# ipro6s register map
Vendor: intelpro; Series: IPRO6S
CPU: ipro6s, little endian
Registers are 32-bit, read-write, reset 0x0 unless marked. A register's access mark holds for its fields unless they carry their own. Offsets are from the block's base; [hi:lo] are bit positions; {n}, {i} and the like mark numbered series.

## MJCOMB_CSR
Base 0x3001A000
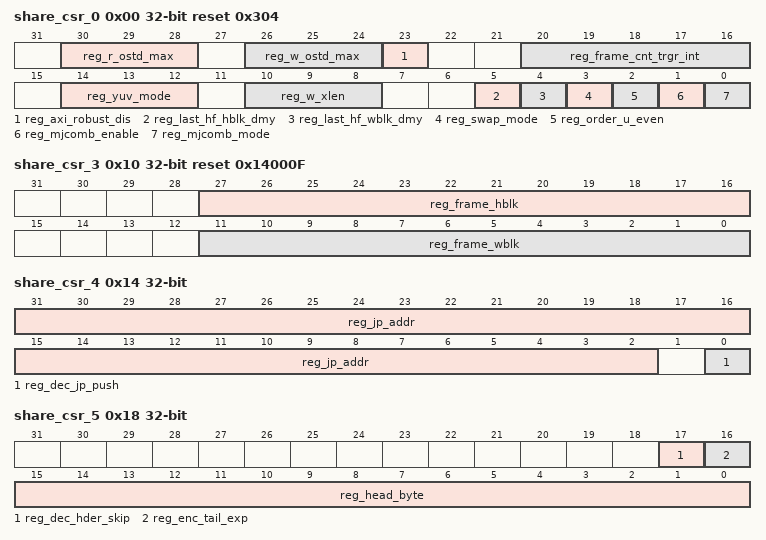
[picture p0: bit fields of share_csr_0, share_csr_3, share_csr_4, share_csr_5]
0x00 share_csr_0 reset 0x304
  [30:28] reg_r_ostd_max — Reserved for HW
  [26:24] reg_w_ostd_max — Reserved for HW
  [23] reg_axi_robust_dis — Reserved for HW
  [20:16] reg_frame_cnt_trgr_int — Frame threshold to issue interrupt
  [14:12] reg_yuv_mode — YUV format setting 3'd0 : YUV420 Semi-Planar 3'd1 : YUV400 grey scale 3'd2 : YUV422 Semi-Planar 3'd3 : INTV422 (Only for JENC) 3'd4 : YUV420 Block mode (Only for JENC) others : Reserved
  [10:8] reg_w_xlen — AXI burst length setting 3'd0-Single / 3'd1-INCR4 / 3'd2-INCR8 3'd3 - INCR16 / Others - RSVD
  [5] reg_last_hf_hblk_dmy — MJPEG last half vertical block with dummy data 8'h80
  [4] reg_last_hf_wblk_dmy — MJPEG last half horizational block with dummy data 8'h80
  [3] reg_swap_mode — ENC : Bitstream write swap mode JDEC YUV Memory swap mode
  [2] reg_order_u_even — 1'b0 - U is odd byte of UV frame / V is even byte of UV frame 1'b1 - U is even byte of UV frame / V is odd byte of UV frame
  [1] reg_mjcomb_enable — MJPEG enable
  [0] reg_mjcomb_mode — MJPEG Mode 1'b0 - Encode mode 1'b1 - Decode mode
0x08 share_csr_1 reset 0x80000000
  [31:0] reg_yy_addr_start — Memory start address of Y frame
0x0C share_csr_2 reset 0x80000000
  [31:0] reg_uv_addr_start — Memory start address of UV frame
0x10 share_csr_3 reset 0x14000F
  [27:16] reg_frame_hblk — Frame total vertical block count
  [11:0] reg_frame_wblk — Frame total horizational block count
0x14 share_csr_4
  [31:2] reg_jp_addr — Memory start address of JPEG stream Decode :
  [0] reg_dec_jp_push wo — (only for Decode)Wrire this bit with 1'b1 to push jpg frame
0x18 share_csr_5
  [17] reg_dec_hder_skip — Skip JPEG stream header enable
  [16] reg_enc_tail_exp — Auto fill tail 0xFF and 0xD9
  [15:0] reg_head_byte — ENC - Preserve head memory space for each frame DEC - Skip JPEG stream header byte
0x40 jstr_check_sum reset not defined
  [31:0] st_jstr_check_sum ro — check sum result
0x44 jstr_check_xor reset not defined
  [31:0] st_jstr_check_xor ro — check sum result
0x48 yuv_check_sum reset not defined
  [31:0] st_yuv_check_sum ro — check sum result
0x4C yuv_check_xor reset not defined
  [31:0] st_yuv_check_xor ro — check sum result
0x7C share_csr_e reset 0xF0
  [7:0] dummy_reg — Dummy R/W register
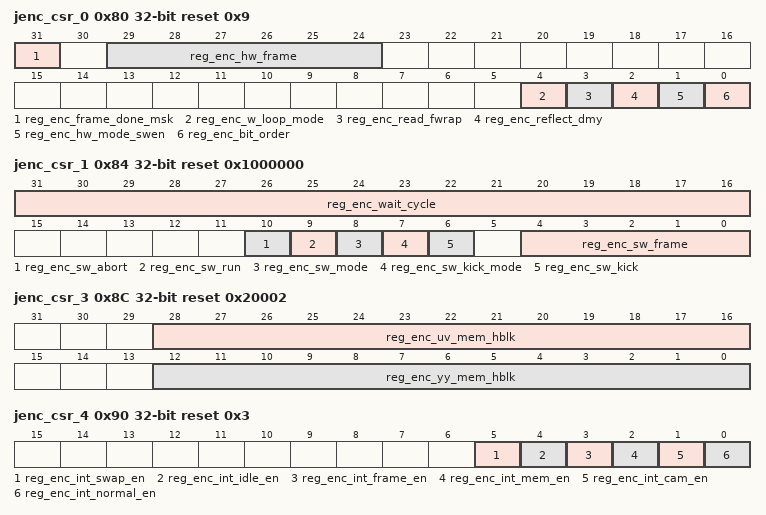
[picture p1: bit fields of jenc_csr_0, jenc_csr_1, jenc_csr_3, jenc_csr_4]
0x80 jenc_csr_0 reset 0x9
  [31] reg_enc_frame_done_msk — Reserved for HW option
  [29:24] reg_enc_hw_frame — Non-SW mode frame cnt 0 - Non auto stop
  [4] reg_enc_w_loop_mode — Write bitstream loop mode enable
  [3] reg_enc_read_fwrap — Only effect in non SW mode This bit determine whether YUV frame read start @ start address
  [2] reg_enc_reflect_dmy — UV dummy with relect
  [1] reg_enc_hw_mode_swen — Only word In hardware mode. SW enable immediately to skip waiting first frame done
  [0] reg_enc_bit_order — MJPEG bitstream byte order adjustment
0x84 jenc_csr_1 reset 0x1000000
  [31:16] reg_enc_wait_cycle — Cycle count in wait state
  [10] reg_enc_sw_abort — MJPEG SW mode abort
  [9] reg_enc_sw_run — MJPEG SW mode run (should enable reg_mjpeg_sw_mode before reg_mjpeg_sw_run)
  [8] reg_enc_sw_mode — MJPEG SW mode enable (should enable reg_mjpeg_sw_mode before reg_mjpeg_sw_run)
  [7] reg_enc_sw_kick_mode — MJPEG SW mode hblk kick mode 1'b0 - SW frame mode 1'b1 - SW kick mode
  [6] reg_enc_sw_kick wo — MJPEG SW mode hblk kick
  [4:0] reg_enc_sw_frame — MJPEG SW mode frame count Only effect when reg_enc_sw_mode==1 && reg_enc_sw_kick_mode==0
0x88 jenc_csr_2 reset 0x4000
  [31:0] reg_enc_jstr_burst_cnt — Memory to store jpeg image burst count
0x8C jenc_csr_3 reset 0x20002
  [28:16] reg_enc_uv_mem_hblk — Memory to store block line for UV frame
  [12:0] reg_enc_yy_mem_hblk — Memory to store block line for Y frame
0x90 jenc_csr_4 reset 0x3
  [5] reg_enc_int_swap_en — Swap memory block interrupt enable
  [4] reg_enc_int_idle_en — Back idle interrupt enable
  [3] reg_enc_int_frame_en — Frame OverWrite interrupt enable
  [2] reg_enc_int_mem_en — JPEG frame memory OverWrite interrupt enable
  [1] reg_enc_int_cam_en — YUV frame memory OverWrite interrupt enable (fatal)
  [0] reg_enc_int_normal_en — Normal Write interrupt enable
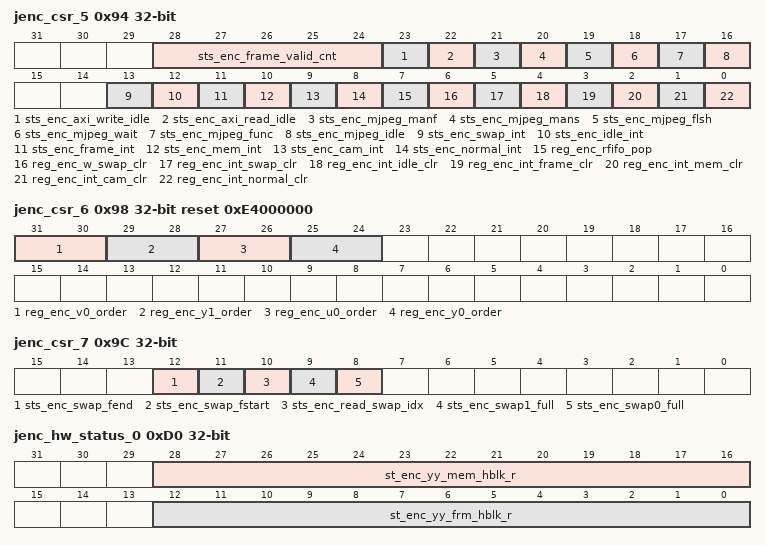
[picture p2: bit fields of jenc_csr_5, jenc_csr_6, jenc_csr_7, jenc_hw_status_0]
0x94 jenc_csr_5 (reset mask 0xFF)
  [28:24] sts_enc_frame_valid_cnt ro — Frame count valid in status
  [23] sts_enc_axi_write_idle ro — AXI write bus idle state
  [22] sts_enc_axi_read_idle ro — AXI read bus idle state
  [21] sts_enc_mjpeg_manf ro — MJPEG in SW run state
  [20] sts_enc_mjpeg_mans ro — MJPEG in SW set state
  [19] sts_enc_mjpeg_flsh ro — MJPEG in flush state
  [18] sts_enc_mjpeg_wait ro — MJPEG in wait state
  [17] sts_enc_mjpeg_func ro — MJPEG in HW function state
  [16] sts_enc_mjpeg_idle ro — MJPEG in idle state
  [13] sts_enc_swap_int ro — Swap memory block interrupt status
  [12] sts_enc_idle_int ro — Normal Write interrupt status
  [11] sts_enc_frame_int ro — Frame OverWrite interrupt status
  [10] sts_enc_mem_int ro — Memory OverWrite interrupt status
  [9] sts_enc_cam_int ro — CAM OverWrite interrupt status (fatal)
  [8] sts_enc_normal_int ro — Normal Write interrupt status
  [7] reg_enc_rfifo_pop wo — Write this bit with 1'b1 to trigger JPEG frame fifo pop
  [6] reg_enc_w_swap_clr wo — Free current read memory block
  [5] reg_enc_int_swap_clr wo — Wrire this bit with 1'b1 to trigger swap interrupt clear
  [4] reg_enc_int_idle_clr wo — Wrire this bit with 1'b1 to trigger back idle interrupt clear
  [3] reg_enc_int_frame_clr wo — Wrire this bit with 1'b1 to trigger frame overwrite interrupt clear
  [2] reg_enc_int_mem_clr wo — Wrire this bit with 1'b1 to trigger memory overwrite interrupt clear
  [1] reg_enc_int_cam_clr wo — Wrire this bit with 1'b1 to trigger YUV overwrite interrupt clear
  [0] reg_enc_int_normal_clr wo — Wrire this bit with 1'b1 to trigger normal interrupt clear
0x98 jenc_csr_6 reset 0xE4000000
  [31:30] reg_enc_v0_order — V order in Interleave mode (only effect when reg_yuv_mode==INTV422)
  [29:28] reg_enc_y1_order — Y1 order in Interleave mode (only effect when reg_yuv_mode==INTV422)
  [27:26] reg_enc_u0_order — U order in Interleave mode (only effect when reg_yuv_mode==INTV422)
  [25:24] reg_enc_y0_order — Y0 order in Interleave mode (only effect when reg_yuv_mode==INTV422)
0x9C jenc_csr_7 reset not defined
  [12] sts_enc_swap_fend ro — Current read memory block is frame end
  [11] sts_enc_swap_fstart ro — Current read memory block is frame start
  [10] sts_enc_read_swap_idx ro — Current read memory block index 0 - memory block0 1 - memory block1
  [9] sts_enc_swap1_full ro — Memory block1 is full
  [8] sts_enc_swap0_full ro — Memory block0 is full
0xA0 jenc_csr_8 reset not defined
  [31:0] sts_enc_frame_swap_end_bit_cnt ro — In swap mode frame remain bit count in last block Only valid when "sts_swap_fend==1"
0xA4 jenc_csr_9 reset 0x2
  [12:0] reg_enc_sw_kick_hblk — Memory to store block line for frame on SW kick
0xA8 jenc_csr_10 reset not defined
  [31:0] sts_enc_frame_start_addr_0 ro — MJPEG FRAME0 Start address
0xAC jenc_csr_11 reset not defined
  [31:0] sts_enc_frame_bit_cnt_0 ro — MJPEG FRAME0 total bit count
0xB0 jenc_csr_12 reset not defined
  [31:0] sts_enc_frame_start_addr_1 ro — MJPEG FRAME1 Start address
0xB4 jenc_csr_13 reset not defined
  [31:0] sts_enc_frame_bit_cnt_1 ro — MJPEG FRAME1 total bit count
0xB8 jenc_csr_14 reset not defined
  [31:0] sts_enc_frame_start_addr_2 ro — MJPEG FRAME2 Start address
0xBC jenc_csr_15 reset not defined
  [31:0] sts_enc_frame_bit_cnt_2 ro — MJPEG FRAME2 total bit count
0xC0 jenc_csr_16 reset not defined
  [31:0] sts_enc_frame_start_addr_3 ro — MJPEG FRAME3 Start address
0xC4 jenc_csr_17 reset not defined
  [31:0] sts_enc_frame_bit_cnt_3 ro — MJPEG FRAME3 total bit count
0xD0 jenc_hw_status_0 reset not defined
  [28:16] st_enc_yy_mem_hblk_r ro — HW status
  [12:0] st_enc_yy_frm_hblk_r ro — HW status
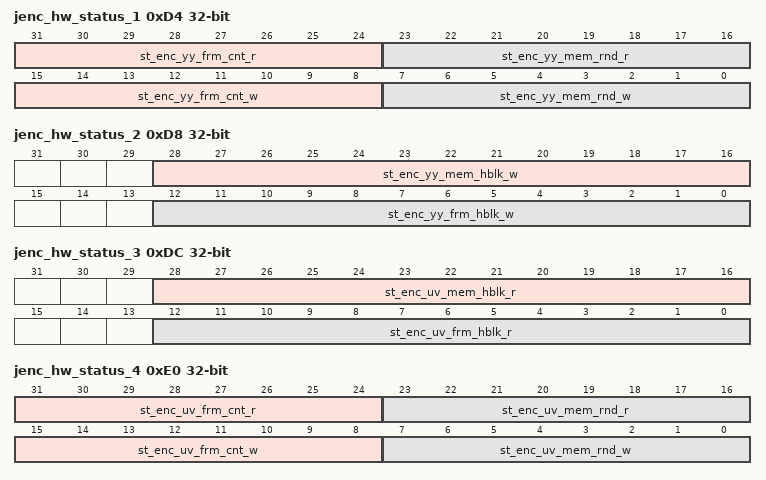
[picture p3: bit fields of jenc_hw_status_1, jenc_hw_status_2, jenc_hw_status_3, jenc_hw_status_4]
0xD4 jenc_hw_status_1 reset not defined
  [31:24] st_enc_yy_frm_cnt_r ro — HW status
  [23:16] st_enc_yy_mem_rnd_r ro — HW status
  [15:8] st_enc_yy_frm_cnt_w ro — HW status
  [7:0] st_enc_yy_mem_rnd_w ro — HW status
0xD8 jenc_hw_status_2 reset not defined
  [28:16] st_enc_yy_mem_hblk_w ro — HW status
  [12:0] st_enc_yy_frm_hblk_w ro — HW status
0xDC jenc_hw_status_3 reset not defined
  [28:16] st_enc_uv_mem_hblk_r ro — HW status
  [12:0] st_enc_uv_frm_hblk_r ro — HW status
0xE0 jenc_hw_status_4 reset not defined
  [31:24] st_enc_uv_frm_cnt_r ro — HW status
  [23:16] st_enc_uv_mem_rnd_r ro — HW status
  [15:8] st_enc_uv_frm_cnt_w ro — HW status
  [7:0] st_enc_uv_mem_rnd_w ro — HW status
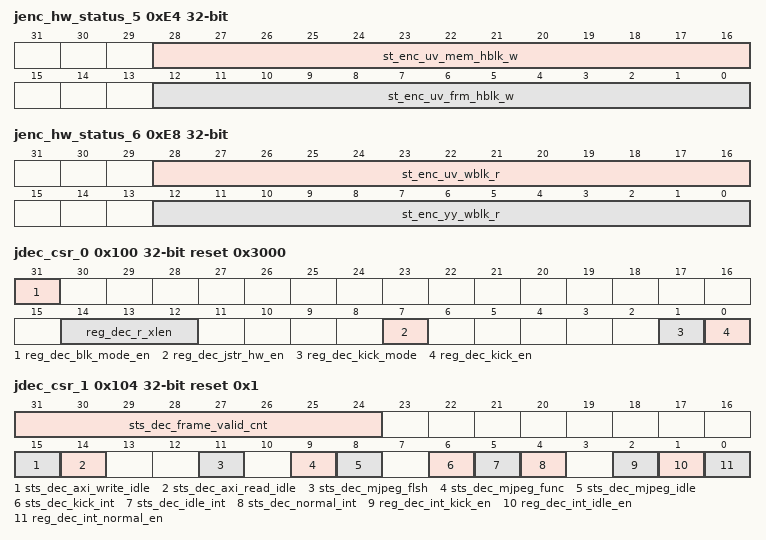
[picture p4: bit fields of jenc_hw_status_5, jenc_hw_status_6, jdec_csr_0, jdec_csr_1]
0xE4 jenc_hw_status_5 reset not defined
  [28:16] st_enc_uv_mem_hblk_w ro — HW status
  [12:0] st_enc_uv_frm_hblk_w ro — HW status
0xE8 jenc_hw_status_6 reset not defined
  [28:16] st_enc_uv_wblk_r ro — HW status
  [12:0] st_enc_yy_wblk_r ro — HW status
0x100 jdec_csr_0 reset 0x3000
  [31] reg_dec_blk_mode_en — JDEC block output mode enable
  [14:12] reg_dec_r_xlen — AXI read burst length setting 3'd0-Single / 3'd1-INCR4 / 3'd2-INCR8 3'd3 - INCR16 / Others - RSVD
  [7] reg_dec_jstr_hw_en — JDEC auto co-work with encode engine mode enable
  [1] reg_dec_kick_mode — JDEC SW control flow kick unit : YUV422 - 1'b0 : Y - 128x8 / UV - 128x8 1'b1 : Block line mode YUV420 - 1'b0 : Y - 128x16 / UV - 128x8 1'b1 : Block line mode
  [0] reg_dec_kick_en — JDEC SW control flow kick mode enable
0x104 jdec_csr_1 reset 0x1 (reset mask 0x7)
  [31:24] sts_dec_frame_valid_cnt ro — Frame count valid in status
  [15] sts_dec_axi_write_idle ro — AXI write bus idle state
  [14] sts_dec_axi_read_idle ro — AXI read bus idle state
  [11] sts_dec_mjpeg_flsh ro — MJPEG in flush state
  [9] sts_dec_mjpeg_func ro — MJPEG in HW function state
  [8] sts_dec_mjpeg_idle ro — MJPEG in idle state
  [6] sts_dec_kick_int ro — Interrupt status
  [5] sts_dec_idle_int ro — Interrupt status
  [4] sts_dec_normal_int ro — Interrupt status
  [2] reg_dec_int_kick_en — Kick mode interrupt enable
  [1] reg_dec_int_idle_en — Back idle interrupt enable
  [0] reg_dec_int_normal_en — Normal Write interrupt enable
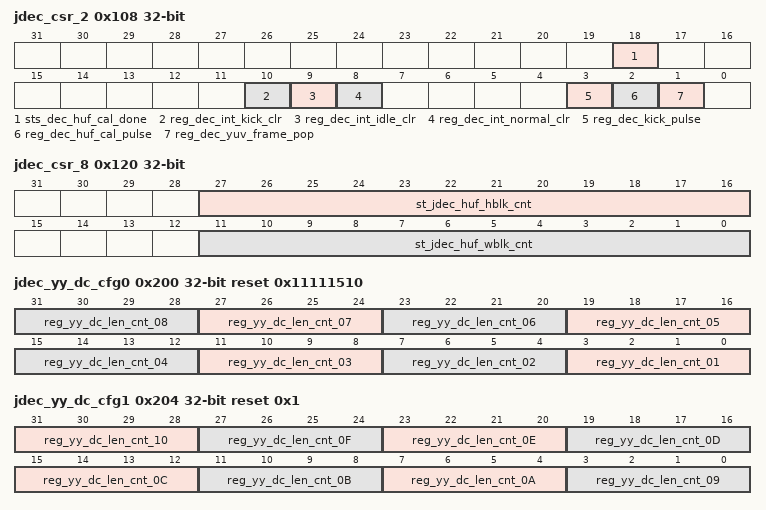
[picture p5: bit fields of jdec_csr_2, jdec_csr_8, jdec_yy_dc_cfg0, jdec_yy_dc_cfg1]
0x108 jdec_csr_2 (reset mask 0x70E)
  [18] sts_dec_huf_cal_done ro — Huffman Table calculation done
  [10] reg_dec_int_kick_clr wo — Wrire this bit with 1'b1 to trigger interrupt clear
  [9] reg_dec_int_idle_clr wo — Wrire this bit with 1'b1 to trigger interrupt clear
  [8] reg_dec_int_normal_clr wo — Wrire this bit with 1'b1 to trigger interrupt clear
  [3] reg_dec_kick_pulse wo — JDEC SW control flow kick mode - SW kick to enable one hblk line write out
  [2] reg_dec_huf_cal_pulse wo — Huffman Table calculation
  [1] reg_dec_yuv_frame_pop wo — Wrire this bit with 1'b1 to pop yuv frame cnt
0x10C jdec_csr_3 reset not defined
  [2:0] sts_dec_jp_frame_cnt ro — JPEG FIFO frame cnt
{0x100+4i} jdec_csr_{i} reset not defined (i=4..7)
  [31:0] sts_dec_jp_addr_{i-4} ro — JPEG PIC {i-4} Start address
0x120 jdec_csr_8 reset not defined
  [27:16] st_jdec_huf_hblk_cnt ro — HW status
  [11:0] st_jdec_huf_wblk_cnt ro — HW status
0x200 jdec_yy_dc_cfg0 reset 0x11111510
  [4n-1:4n-4] reg_yy_dc_len_cnt_{n:02} (n=1..8) — Length count of huffman table
0x204 jdec_yy_dc_cfg1 reset 0x1
  [31:28] reg_yy_dc_len_cnt_10 — Length count of huffman table
  [27:24] reg_yy_dc_len_cnt_0F — Length count of huffman table
  [23:20] reg_yy_dc_len_cnt_0E — Length count of huffman table
  [19:16] reg_yy_dc_len_cnt_0D — Length count of huffman table
  [15:12] reg_yy_dc_len_cnt_0C — Length count of huffman table
  [11:8] reg_yy_dc_len_cnt_0B — Length count of huffman table
  [7:4] reg_yy_dc_len_cnt_0A — Length count of huffman table
  [3:0] reg_yy_dc_len_cnt_09 — Length count of huffman table
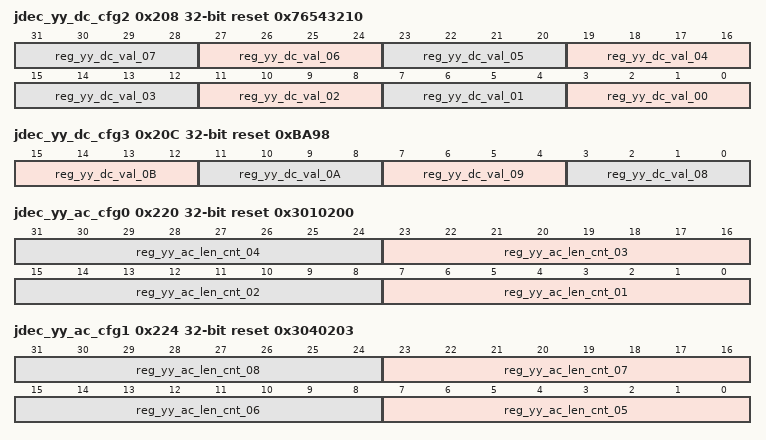
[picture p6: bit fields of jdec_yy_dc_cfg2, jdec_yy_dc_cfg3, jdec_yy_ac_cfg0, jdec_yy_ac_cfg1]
0x208 jdec_yy_dc_cfg2 reset 0x76543210
  [4n+3:4n] reg_yy_dc_val_{n:02} (n=0..7) — Value of huffman table
0x20C jdec_yy_dc_cfg3 reset 0xBA98
  [15:12] reg_yy_dc_val_0B — Value of huffman table
  [11:8] reg_yy_dc_val_0A — Value of huffman table
  [7:4] reg_yy_dc_val_09 — Value of huffman table
  [3:0] reg_yy_dc_val_08 — Value of huffman table
0x220 jdec_yy_ac_cfg0 reset 0x3010200
  [8n-1:8n-8] reg_yy_ac_len_cnt_{n:02} (n=1..4) — Length count of huffman table
0x224 jdec_yy_ac_cfg1 reset 0x3040203
  [8n-33:8n-40] reg_yy_ac_len_cnt_{n:02} (n=5..8) — Length count of huffman table
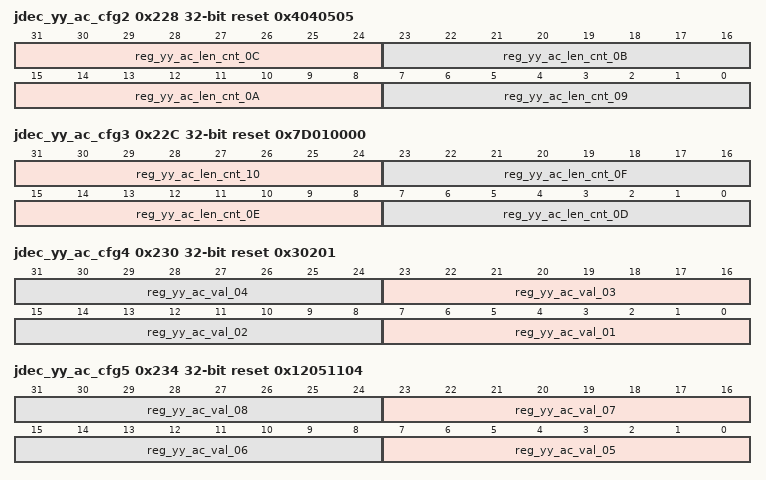
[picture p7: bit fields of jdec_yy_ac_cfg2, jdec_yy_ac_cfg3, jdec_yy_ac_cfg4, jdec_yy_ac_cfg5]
0x228 jdec_yy_ac_cfg2 reset 0x4040505
  [31:24] reg_yy_ac_len_cnt_0C — Length count of huffman table
  [23:16] reg_yy_ac_len_cnt_0B — Length count of huffman table
  [15:8] reg_yy_ac_len_cnt_0A — Length count of huffman table
  [7:0] reg_yy_ac_len_cnt_09 — Length count of huffman table
0x22C jdec_yy_ac_cfg3 reset 0x7D010000
  [31:24] reg_yy_ac_len_cnt_10 — Length count of huffman table
  [23:16] reg_yy_ac_len_cnt_0F — Length count of huffman table
  [15:8] reg_yy_ac_len_cnt_0E — Length count of huffman table
  [7:0] reg_yy_ac_len_cnt_0D — Length count of huffman table
0x230 jdec_yy_ac_cfg4 reset 0x30201
  [8n-1:8n-8] reg_yy_ac_val_{n:02} (n=1..4) — Value of huffman table
0x234 jdec_yy_ac_cfg5 reset 0x12051104
  [8n-33:8n-40] reg_yy_ac_val_{n:02} (n=5..8) — Value of huffman table
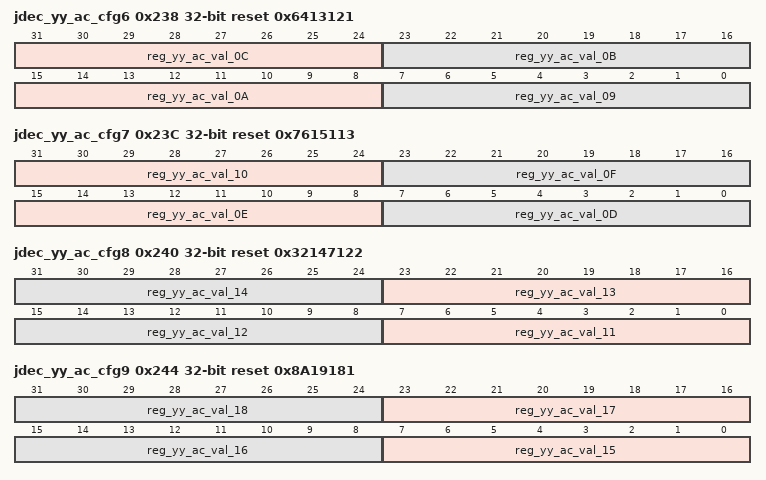
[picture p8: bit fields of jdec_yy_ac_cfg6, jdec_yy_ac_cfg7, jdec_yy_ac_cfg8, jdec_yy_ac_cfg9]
0x238 jdec_yy_ac_cfg6 reset 0x6413121
  [31:24] reg_yy_ac_val_0C — Value of huffman table
  [23:16] reg_yy_ac_val_0B — Value of huffman table
  [15:8] reg_yy_ac_val_0A — Value of huffman table
  [7:0] reg_yy_ac_val_09 — Value of huffman table
0x23C jdec_yy_ac_cfg7 reset 0x7615113
  [31:24] reg_yy_ac_val_10 — Value of huffman table
  [23:16] reg_yy_ac_val_0F — Value of huffman table
  [15:8] reg_yy_ac_val_0E — Value of huffman table
  [7:0] reg_yy_ac_val_0D — Value of huffman table
0x240 jdec_yy_ac_cfg8 reset 0x32147122
  [8n-81:8n-88] reg_yy_ac_val_{n} (n=11..14) — Value of huffman table
0x244 jdec_yy_ac_cfg9 reset 0x8A19181
  [8n-113:8n-120] reg_yy_ac_val_{n} (n=15..18) — Value of huffman table
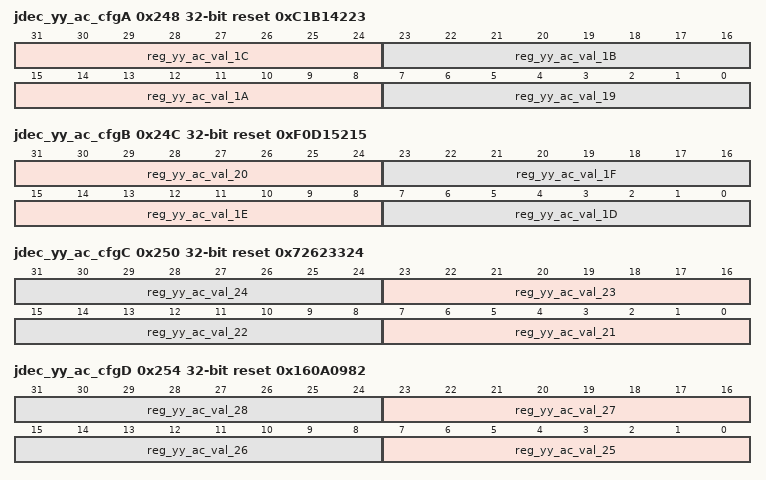
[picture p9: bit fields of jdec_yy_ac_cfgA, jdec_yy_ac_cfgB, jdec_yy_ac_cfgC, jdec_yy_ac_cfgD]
0x248 jdec_yy_ac_cfgA reset 0xC1B14223
  [31:24] reg_yy_ac_val_1C — Value of huffman table
  [23:16] reg_yy_ac_val_1B — Value of huffman table
  [15:8] reg_yy_ac_val_1A — Value of huffman table
  [7:0] reg_yy_ac_val_19 — Value of huffman table
0x24C jdec_yy_ac_cfgB reset 0xF0D15215
  [31:24] reg_yy_ac_val_20 — Value of huffman table
  [23:16] reg_yy_ac_val_1F — Value of huffman table
  [15:8] reg_yy_ac_val_1E — Value of huffman table
  [7:0] reg_yy_ac_val_1D — Value of huffman table
0x250 jdec_yy_ac_cfgC reset 0x72623324
  [8n-161:8n-168] reg_yy_ac_val_{n} (n=21..24) — Value of huffman table
0x254 jdec_yy_ac_cfgD reset 0x160A0982
  [8n-193:8n-200] reg_yy_ac_val_{n} (n=25..28) — Value of huffman table
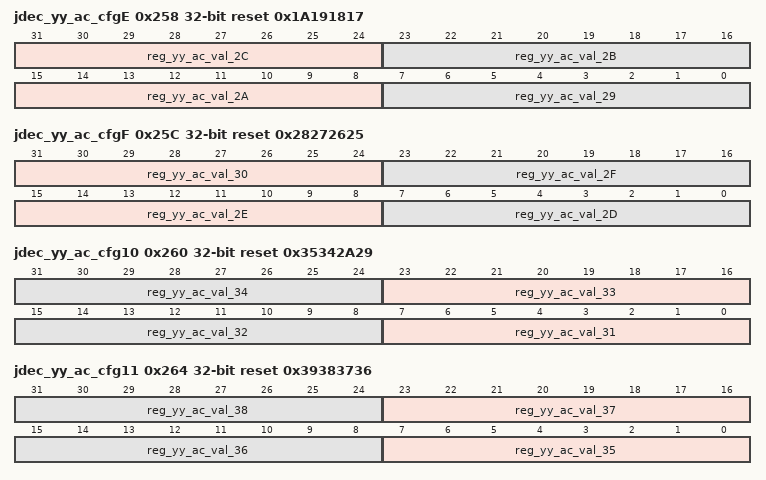
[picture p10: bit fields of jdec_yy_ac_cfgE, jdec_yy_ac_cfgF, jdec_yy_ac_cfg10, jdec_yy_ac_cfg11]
0x258 jdec_yy_ac_cfgE reset 0x1A191817
  [31:24] reg_yy_ac_val_2C — Value of huffman table
  [23:16] reg_yy_ac_val_2B — Value of huffman table
  [15:8] reg_yy_ac_val_2A — Value of huffman table
  [7:0] reg_yy_ac_val_29 — Value of huffman table
0x25C jdec_yy_ac_cfgF reset 0x28272625
  [31:24] reg_yy_ac_val_30 — Value of huffman table
  [23:16] reg_yy_ac_val_2F — Value of huffman table
  [15:8] reg_yy_ac_val_2E — Value of huffman table
  [7:0] reg_yy_ac_val_2D — Value of huffman table
0x260 jdec_yy_ac_cfg10 reset 0x35342A29
  [8n-241:8n-248] reg_yy_ac_val_{n} (n=31..34) — Value of huffman table
0x264 jdec_yy_ac_cfg11 reset 0x39383736
  [8n-273:8n-280] reg_yy_ac_val_{n} (n=35..38) — Value of huffman table
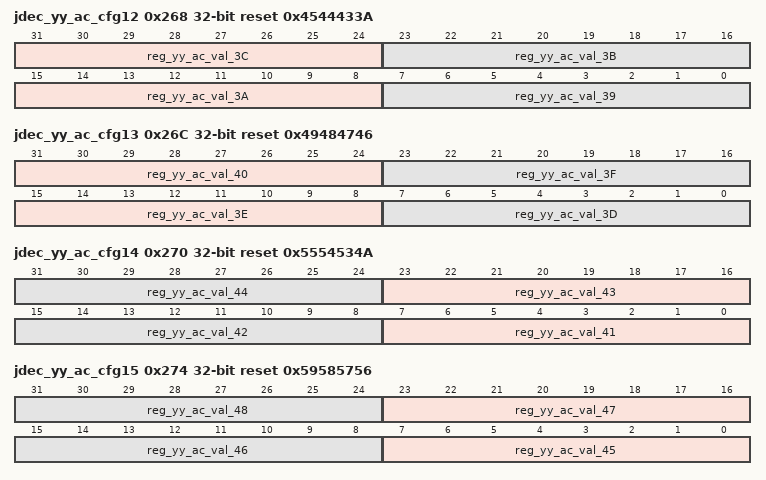
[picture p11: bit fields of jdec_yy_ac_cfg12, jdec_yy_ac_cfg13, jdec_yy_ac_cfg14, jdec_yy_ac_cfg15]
0x268 jdec_yy_ac_cfg12 reset 0x4544433A
  [31:24] reg_yy_ac_val_3C — Value of huffman table
  [23:16] reg_yy_ac_val_3B — Value of huffman table
  [15:8] reg_yy_ac_val_3A — Value of huffman table
  [7:0] reg_yy_ac_val_39 — Value of huffman table
0x26C jdec_yy_ac_cfg13 reset 0x49484746
  [31:24] reg_yy_ac_val_40 — Value of huffman table
  [23:16] reg_yy_ac_val_3F — Value of huffman table
  [15:8] reg_yy_ac_val_3E — Value of huffman table
  [7:0] reg_yy_ac_val_3D — Value of huffman table
0x270 jdec_yy_ac_cfg14 reset 0x5554534A
  [8n-321:8n-328] reg_yy_ac_val_{n} (n=41..44) — Value of huffman table
0x274 jdec_yy_ac_cfg15 reset 0x59585756
  [8n-353:8n-360] reg_yy_ac_val_{n} (n=45..48) — Value of huffman table
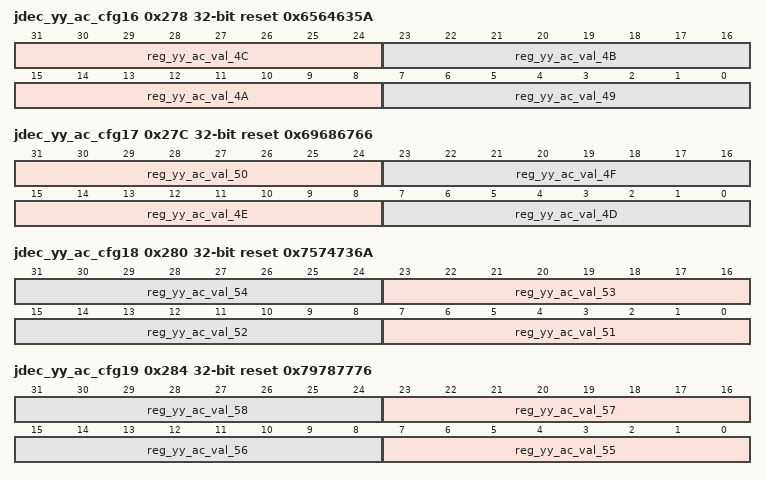
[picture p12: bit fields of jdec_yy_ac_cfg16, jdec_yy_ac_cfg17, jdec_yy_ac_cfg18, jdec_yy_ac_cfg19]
0x278 jdec_yy_ac_cfg16 reset 0x6564635A
  [31:24] reg_yy_ac_val_4C — Value of huffman table
  [23:16] reg_yy_ac_val_4B — Value of huffman table
  [15:8] reg_yy_ac_val_4A — Value of huffman table
  [7:0] reg_yy_ac_val_49 — Value of huffman table
0x27C jdec_yy_ac_cfg17 reset 0x69686766
  [31:24] reg_yy_ac_val_50 — Value of huffman table
  [23:16] reg_yy_ac_val_4F — Value of huffman table
  [15:8] reg_yy_ac_val_4E — Value of huffman table
  [7:0] reg_yy_ac_val_4D — Value of huffman table
0x280 jdec_yy_ac_cfg18 reset 0x7574736A
  [8n-401:8n-408] reg_yy_ac_val_{n} (n=51..54) — Value of huffman table
0x284 jdec_yy_ac_cfg19 reset 0x79787776
  [8n-433:8n-440] reg_yy_ac_val_{n} (n=55..58) — Value of huffman table
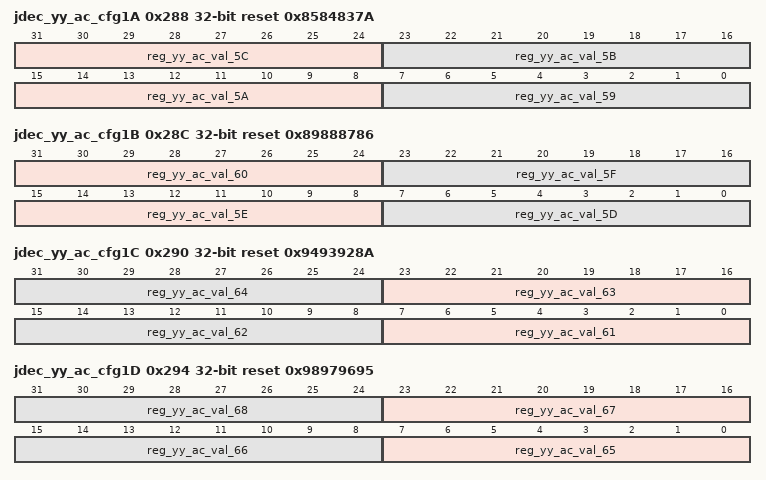
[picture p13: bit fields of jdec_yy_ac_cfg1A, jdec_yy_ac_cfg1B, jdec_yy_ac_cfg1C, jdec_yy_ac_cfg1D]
0x288 jdec_yy_ac_cfg1A reset 0x8584837A
  [31:24] reg_yy_ac_val_5C — Value of huffman table
  [23:16] reg_yy_ac_val_5B — Value of huffman table
  [15:8] reg_yy_ac_val_5A — Value of huffman table
  [7:0] reg_yy_ac_val_59 — Value of huffman table
0x28C jdec_yy_ac_cfg1B reset 0x89888786
  [31:24] reg_yy_ac_val_60 — Value of huffman table
  [23:16] reg_yy_ac_val_5F — Value of huffman table
  [15:8] reg_yy_ac_val_5E — Value of huffman table
  [7:0] reg_yy_ac_val_5D — Value of huffman table
0x290 jdec_yy_ac_cfg1C reset 0x9493928A
  [8n-481:8n-488] reg_yy_ac_val_{n} (n=61..64) — Value of huffman table
0x294 jdec_yy_ac_cfg1D reset 0x98979695
  [8n-513:8n-520] reg_yy_ac_val_{n} (n=65..68) — Value of huffman table
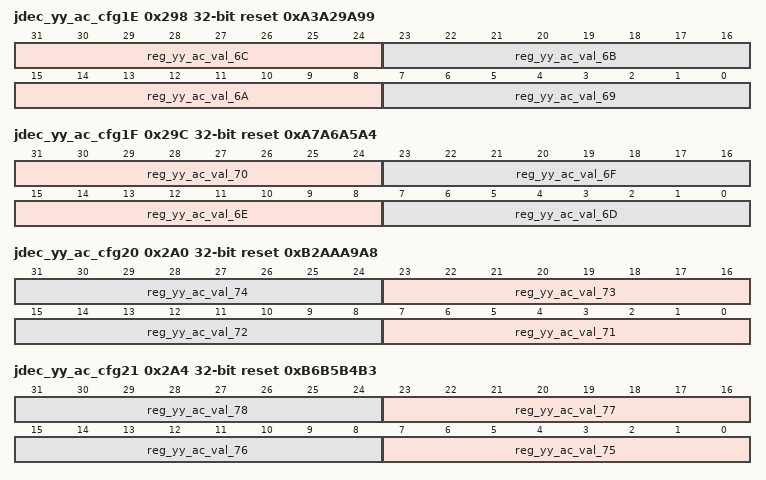
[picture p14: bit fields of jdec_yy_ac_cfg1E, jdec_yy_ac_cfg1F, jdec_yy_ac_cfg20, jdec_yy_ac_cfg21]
0x298 jdec_yy_ac_cfg1E reset 0xA3A29A99
  [31:24] reg_yy_ac_val_6C — Value of huffman table
  [23:16] reg_yy_ac_val_6B — Value of huffman table
  [15:8] reg_yy_ac_val_6A — Value of huffman table
  [7:0] reg_yy_ac_val_69 — Value of huffman table
0x29C jdec_yy_ac_cfg1F reset 0xA7A6A5A4
  [31:24] reg_yy_ac_val_70 — Value of huffman table
  [23:16] reg_yy_ac_val_6F — Value of huffman table
  [15:8] reg_yy_ac_val_6E — Value of huffman table
  [7:0] reg_yy_ac_val_6D — Value of huffman table
0x2A0 jdec_yy_ac_cfg20 reset 0xB2AAA9A8
  [8n-561:8n-568] reg_yy_ac_val_{n} (n=71..74) — Value of huffman table
0x2A4 jdec_yy_ac_cfg21 reset 0xB6B5B4B3
  [8n-593:8n-600] reg_yy_ac_val_{n} (n=75..78) — Value of huffman table
0x2A8 jdec_yy_ac_cfg22 reset 0xBAB9B8B7
  [31:24] reg_yy_ac_val_7C — Value of huffman table
  [23:16] reg_yy_ac_val_7B — Value of huffman table
  [15:8] reg_yy_ac_val_7A — Value of huffman table
  [7:0] reg_yy_ac_val_79 — Value of huffman table
0x2AC jdec_yy_ac_cfg23 reset 0xC5C4C3C2
  [31:24] reg_yy_ac_val_80 — Value of huffman table
  [23:16] reg_yy_ac_val_7F — Value of huffman table
  [15:8] reg_yy_ac_val_7E — Value of huffman table
  [7:0] reg_yy_ac_val_7D — Value of huffman table
0x2B0 jdec_yy_ac_cfg24 reset 0xC9C8C7C6
  [8n-641:8n-648] reg_yy_ac_val_{n} (n=81..84) — Value of huffman table
0x2B4 jdec_yy_ac_cfg25 reset 0xD4D3D2CA
  [8n-673:8n-680] reg_yy_ac_val_{n} (n=85..88) — Value of huffman table
0x2B8 jdec_yy_ac_cfg26 reset 0xD8D7D6D5
  [31:24] reg_yy_ac_val_8C — Value of huffman table
  [23:16] reg_yy_ac_val_8B — Value of huffman table
  [15:8] reg_yy_ac_val_8A — Value of huffman table
  [7:0] reg_yy_ac_val_89 — Value of huffman table
0x2BC jdec_yy_ac_cfg27 reset 0xE2E1DAD9
  [31:24] reg_yy_ac_val_90 — Value of huffman table
  [23:16] reg_yy_ac_val_8F — Value of huffman table
  [15:8] reg_yy_ac_val_8E — Value of huffman table
  [7:0] reg_yy_ac_val_8D — Value of huffman table
0x2C0 jdec_yy_ac_cfg28 reset 0xE6E5E4E3
  [8n-721:8n-728] reg_yy_ac_val_{n} (n=91..94) — Value of huffman table
0x2C4 jdec_yy_ac_cfg29 reset 0xEAE9E8E7
  [8n-753:8n-760] reg_yy_ac_val_{n} (n=95..98) — Value of huffman table
0x2C8 jdec_yy_ac_cfg2A reset 0xF4F3F2F1
  [31:24] reg_yy_ac_val_9C — Value of huffman table
  [23:16] reg_yy_ac_val_9B — Value of huffman table
  [15:8] reg_yy_ac_val_9A — Value of huffman table
  [7:0] reg_yy_ac_val_99 — Value of huffman table
0x2CC jdec_yy_ac_cfg2B reset 0xF8F7F6F5
  [31:24] reg_yy_ac_val_A0 — Value of huffman table
  [23:16] reg_yy_ac_val_9F — Value of huffman table
  [15:8] reg_yy_ac_val_9E — Value of huffman table
  [7:0] reg_yy_ac_val_9D — Value of huffman table
0x2D0 jdec_yy_ac_cfg2C reset 0xFAF9
  [15:8] reg_yy_ac_val_A2 — Value of huffman table
  [7:0] reg_yy_ac_val_A1 — Value of huffman table
0x300 jdec_uv_dc_cfg0 reset 0x11111130
  [4n-1:4n-4] reg_uv_dc_len_cnt_{n:02} (n=1..8) — Length count of huffman table
0x304 jdec_uv_dc_cfg1 reset 0x111
  [31:28] reg_uv_dc_len_cnt_10 — Length count of huffman table
  [27:24] reg_uv_dc_len_cnt_0F — Length count of huffman table
  [23:20] reg_uv_dc_len_cnt_0E — Length count of huffman table
  [19:16] reg_uv_dc_len_cnt_0D — Length count of huffman table
  [15:12] reg_uv_dc_len_cnt_0C — Length count of huffman table
  [11:8] reg_uv_dc_len_cnt_0B — Length count of huffman table
  [7:4] reg_uv_dc_len_cnt_0A — Length count of huffman table
  [3:0] reg_uv_dc_len_cnt_09 — Length count of huffman table
0x308 jdec_uv_dc_cfg2 reset 0x76543210
  [4n+3:4n] reg_uv_dc_val_{n:02} (n=0..7) — Value of huffman table
0x30C jdec_uv_dc_cfg3 reset 0xBA98
  [15:12] reg_uv_dc_val_0B — Value of huffman table
  [11:8] reg_uv_dc_val_0A — Value of huffman table
  [7:4] reg_uv_dc_val_09 — Value of huffman table
  [3:0] reg_uv_dc_val_08 — Value of huffman table
0x320 jdec_uv_ac_cfg0 reset 0x2010200
  [8n-1:8n-8] reg_uv_ac_len_cnt_{n:02} (n=1..4) — Length count of huffman table
0x324 jdec_uv_ac_cfg1 reset 0x4030404
  [8n-33:8n-40] reg_uv_ac_len_cnt_{n:02} (n=5..8) — Length count of huffman table
0x328 jdec_uv_ac_cfg2 reset 0x4040507
  [31:24] reg_uv_ac_len_cnt_0C — Length count of huffman table
  [23:16] reg_uv_ac_len_cnt_0B — Length count of huffman table
  [15:8] reg_uv_ac_len_cnt_0A — Length count of huffman table
  [7:0] reg_uv_ac_len_cnt_09 — Length count of huffman table
0x32C jdec_uv_ac_cfg3 reset 0x77020100
  [31:24] reg_uv_ac_len_cnt_10 — Length count of huffman table
  [23:16] reg_uv_ac_len_cnt_0F — Length count of huffman table
  [15:8] reg_uv_ac_len_cnt_0E — Length count of huffman table
  [7:0] reg_uv_ac_len_cnt_0D — Length count of huffman table
0x330 jdec_uv_ac_cfg4 reset 0x3020100
  [8n-1:8n-8] reg_uv_ac_val_{n:02} (n=1..4) — Value of huffman table
0x334 jdec_uv_ac_cfg5 reset 0x21050411
  [8n-33:8n-40] reg_uv_ac_val_{n:02} (n=5..8) — Value of huffman table
0x338 jdec_uv_ac_cfg6 reset 0x41120631
  [31:24] reg_uv_ac_val_0C — Value of huffman table
  [23:16] reg_uv_ac_val_0B — Value of huffman table
  [15:8] reg_uv_ac_val_0A — Value of huffman table
  [7:0] reg_uv_ac_val_09 — Value of huffman table
0x33C jdec_uv_ac_cfg7 reset 0x71610751
  [31:24] reg_uv_ac_val_10 — Value of huffman table
  [23:16] reg_uv_ac_val_0F — Value of huffman table
  [15:8] reg_uv_ac_val_0E — Value of huffman table
  [7:0] reg_uv_ac_val_0D — Value of huffman table
0x340 jdec_uv_ac_cfg8 reset 0x81322213
  [8n-81:8n-88] reg_uv_ac_val_{n} (n=11..14) — Value of huffman table
0x344 jdec_uv_ac_cfg9 reset 0x91421408
  [8n-113:8n-120] reg_uv_ac_val_{n} (n=15..18) — Value of huffman table
0x348 jdec_uv_ac_cfgA reset 0x9C1B1A1
  [31:24] reg_uv_ac_val_1C — Value of huffman table
  [23:16] reg_uv_ac_val_1B — Value of huffman table
  [15:8] reg_uv_ac_val_1A — Value of huffman table
  [7:0] reg_uv_ac_val_19 — Value of huffman table
0x34C jdec_uv_ac_cfgB reset 0xF0523323
  [31:24] reg_uv_ac_val_20 — Value of huffman table
  [23:16] reg_uv_ac_val_1F — Value of huffman table
  [15:8] reg_uv_ac_val_1E — Value of huffman table
  [7:0] reg_uv_ac_val_1D — Value of huffman table
0x350 jdec_uv_ac_cfgC reset 0xD1726215
  [8n-161:8n-168] reg_uv_ac_val_{n} (n=21..24) — Value of huffman table
0x354 jdec_uv_ac_cfgD reset 0x3424160A
  [8n-193:8n-200] reg_uv_ac_val_{n} (n=25..28) — Value of huffman table
0x358 jdec_uv_ac_cfgE reset 0x17F125E1
  [31:24] reg_uv_ac_val_2C — Value of huffman table
  [23:16] reg_uv_ac_val_2B — Value of huffman table
  [15:8] reg_uv_ac_val_2A — Value of huffman table
  [7:0] reg_uv_ac_val_29 — Value of huffman table
0x35C jdec_uv_ac_cfgF reset 0x261A1918
  [31:24] reg_uv_ac_val_30 — Value of huffman table
  [23:16] reg_uv_ac_val_2F — Value of huffman table
  [15:8] reg_uv_ac_val_2E — Value of huffman table
  [7:0] reg_uv_ac_val_2D — Value of huffman table
0x360 jdec_uv_ac_cfg10 reset 0x2A292827
  [8n-241:8n-248] reg_uv_ac_val_{n} (n=31..34) — Value of huffman table
0x364 jdec_uv_ac_cfg11 reset 0x38373635
  [8n-273:8n-280] reg_uv_ac_val_{n} (n=35..38) — Value of huffman table
0x368 jdec_uv_ac_cfg12 reset 0x44433A39
  [31:24] reg_uv_ac_val_3C — Value of huffman table
  [23:16] reg_uv_ac_val_3B — Value of huffman table
  [15:8] reg_uv_ac_val_3A — Value of huffman table
  [7:0] reg_uv_ac_val_39 — Value of huffman table
0x36C jdec_uv_ac_cfg13 reset 0x48474645
  [31:24] reg_uv_ac_val_40 — Value of huffman table
  [23:16] reg_uv_ac_val_3F — Value of huffman table
  [15:8] reg_uv_ac_val_3E — Value of huffman table
  [7:0] reg_uv_ac_val_3D — Value of huffman table
0x370 jdec_uv_ac_cfg14 reset 0x54534A49
  [8n-321:8n-328] reg_uv_ac_val_{n} (n=41..44) — Value of huffman table
0x374 jdec_uv_ac_cfg15 reset 0x58575655
  [8n-353:8n-360] reg_uv_ac_val_{n} (n=45..48) — Value of huffman table
0x378 jdec_uv_ac_cfg16 reset 0x64635A59
  [31:24] reg_uv_ac_val_4C — Value of huffman table
  [23:16] reg_uv_ac_val_4B — Value of huffman table
  [15:8] reg_uv_ac_val_4A — Value of huffman table
  [7:0] reg_uv_ac_val_49 — Value of huffman table
0x37C jdec_uv_ac_cfg17 reset 0x68676665
  [31:24] reg_uv_ac_val_50 — Value of huffman table
  [23:16] reg_uv_ac_val_4F — Value of huffman table
  [15:8] reg_uv_ac_val_4E — Value of huffman table
  [7:0] reg_uv_ac_val_4D — Value of huffman table
0x380 jdec_uv_ac_cfg18 reset 0x74736A69
  [8n-401:8n-408] reg_uv_ac_val_{n} (n=51..54) — Value of huffman table
0x384 jdec_uv_ac_cfg19 reset 0x78777675
  [8n-433:8n-440] reg_uv_ac_val_{n} (n=55..58) — Value of huffman table
0x388 jdec_uv_ac_cfg1A reset 0x83827A79
  [31:24] reg_uv_ac_val_5C — Value of huffman table
  [23:16] reg_uv_ac_val_5B — Value of huffman table
  [15:8] reg_uv_ac_val_5A — Value of huffman table
  [7:0] reg_uv_ac_val_59 — Value of huffman table
0x38C jdec_uv_ac_cfg1B reset 0x87868584
  [31:24] reg_uv_ac_val_60 — Value of huffman table
  [23:16] reg_uv_ac_val_5F — Value of huffman table
  [15:8] reg_uv_ac_val_5E — Value of huffman table
  [7:0] reg_uv_ac_val_5D — Value of huffman table
0x390 jdec_uv_ac_cfg1C reset 0x928A8988
  [8n-481:8n-488] reg_uv_ac_val_{n} (n=61..64) — Value of huffman table
0x394 jdec_uv_ac_cfg1D reset 0x96959493
  [8n-513:8n-520] reg_uv_ac_val_{n} (n=65..68) — Value of huffman table
0x398 jdec_uv_ac_cfg1E reset 0x9A999897
  [31:24] reg_uv_ac_val_6C — Value of huffman table
  [23:16] reg_uv_ac_val_6B — Value of huffman table
  [15:8] reg_uv_ac_val_6A — Value of huffman table
  [7:0] reg_uv_ac_val_69 — Value of huffman table
0x39C jdec_uv_ac_cfg1F reset 0xA5A4A3A2
  [31:24] reg_uv_ac_val_70 — Value of huffman table
  [23:16] reg_uv_ac_val_6F — Value of huffman table
  [15:8] reg_uv_ac_val_6E — Value of huffman table
  [7:0] reg_uv_ac_val_6D — Value of huffman table
0x3A0 jdec_uv_ac_cfg20 reset 0xA9A8A7A6
  [8n-561:8n-568] reg_uv_ac_val_{n} (n=71..74) — Value of huffman table
0x3A4 jdec_uv_ac_cfg21 reset 0xB4B3B2AA
  [8n-593:8n-600] reg_uv_ac_val_{n} (n=75..78) — Value of huffman table
0x3A8 jdec_uv_ac_cfg22 reset 0xB8B7B6B5
  [31:24] reg_uv_ac_val_7C — Value of huffman table
  [23:16] reg_uv_ac_val_7B — Value of huffman table
  [15:8] reg_uv_ac_val_7A — Value of huffman table
  [7:0] reg_uv_ac_val_79 — Value of huffman table
0x3AC jdec_uv_ac_cfg23 reset 0xC3C2BAB9
  [31:24] reg_uv_ac_val_80 — Value of huffman table
  [23:16] reg_uv_ac_val_7F — Value of huffman table
  [15:8] reg_uv_ac_val_7E — Value of huffman table
  [7:0] reg_uv_ac_val_7D — Value of huffman table
0x3B0 jdec_uv_ac_cfg24 reset 0xC7C6C5C4
  [8n-641:8n-648] reg_uv_ac_val_{n} (n=81..84) — Value of huffman table
0x3B4 jdec_uv_ac_cfg25 reset 0xD2CAC9C8
  [8n-673:8n-680] reg_uv_ac_val_{n} (n=85..88) — Value of huffman table
0x3B8 jdec_uv_ac_cfg26 reset 0xD6D5D4D3
  [31:24] reg_uv_ac_val_8C — Value of huffman table
  [23:16] reg_uv_ac_val_8B — Value of huffman table
  [15:8] reg_uv_ac_val_8A — Value of huffman table
  [7:0] reg_uv_ac_val_89 — Value of huffman table
0x3BC jdec_uv_ac_cfg27 reset 0xDAD9D8D7
  [31:24] reg_uv_ac_val_90 — Value of huffman table
  [23:16] reg_uv_ac_val_8F — Value of huffman table
  [15:8] reg_uv_ac_val_8E — Value of huffman table
  [7:0] reg_uv_ac_val_8D — Value of huffman table
0x3C0 jdec_uv_ac_cfg28 reset 0xE5E4E3E2
  [8n-721:8n-728] reg_uv_ac_val_{n} (n=91..94) — Value of huffman table
0x3C4 jdec_uv_ac_cfg29 reset 0xE9E8E7E6
  [8n-753:8n-760] reg_uv_ac_val_{n} (n=95..98) — Value of huffman table
0x3C8 jdec_uv_ac_cfg2A reset 0xF4F3F2EA
  [31:24] reg_uv_ac_val_9C — Value of huffman table
  [23:16] reg_uv_ac_val_9B — Value of huffman table
  [15:8] reg_uv_ac_val_9A — Value of huffman table
  [7:0] reg_uv_ac_val_99 — Value of huffman table
0x3CC jdec_uv_ac_cfg2B reset 0xF8F7F6F5
  [31:24] reg_uv_ac_val_A0 — Value of huffman table
  [23:16] reg_uv_ac_val_9F — Value of huffman table
  [15:8] reg_uv_ac_val_9E — Value of huffman table
  [7:0] reg_uv_ac_val_9D — Value of huffman table
0x3D0 jdec_uv_ac_cfg2C reset 0xFAF9
  [15:8] reg_uv_ac_val_A2 — Value of huffman table
  [7:0] reg_uv_ac_val_A1 — Value of huffman table
